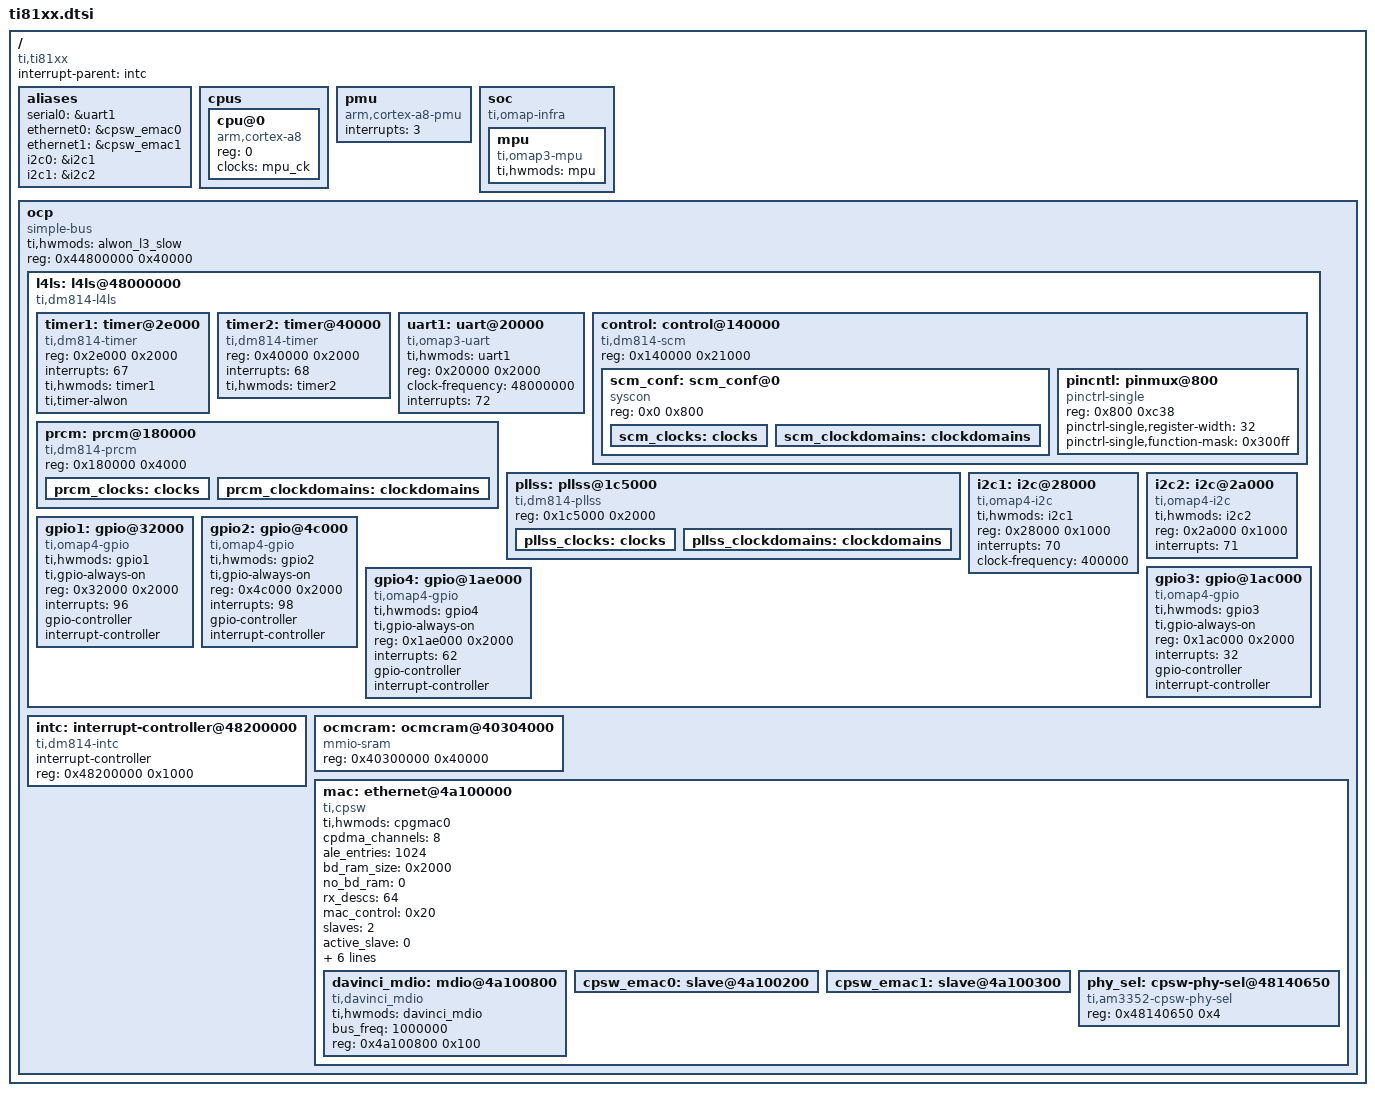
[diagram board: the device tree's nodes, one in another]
/*
 * This file is licensed under the terms of the GNU General Public License
 * version 2.  This program is licensed "as is" without any warranty of any
 * kind, whether express or implied.
 */

#include <dt-bindings/gpio/gpio.h>
#include <dt-bindings/pinctrl/omap.h>

#include "skeleton.dtsi"

/ {
	compatible = "ti,ti81xx";
	interrupt-parent = <&intc>;

	aliases {
		serial0 = &uart1;
		ethernet0 = &cpsw_emac0;
		ethernet1 = &cpsw_emac1;
		i2c0 = &i2c1;
		i2c1 = &i2c2;

	};

	cpus {
		#address-cells = <1>;
		#size-cells = <0>;
		cpu@0 {
			compatible = "arm,cortex-a8";
			device_type = "cpu";
			reg = <0>;
			clocks = <&mpu_ck>;
		};
	};

	pmu {
		compatible = "arm,cortex-a8-pmu";
		interrupts = <3>;
	};

	/*
	 * The soc node represents the soc top level view. It is used for IPs
	 * that are not memory mapped in the MPU view or for the MPU itself.
	 */
	soc {
		compatible = "ti,omap-infra";
		mpu {
			compatible = "ti,omap3-mpu";
			ti,hwmods = "mpu";
		};
	};

	ocp {
		compatible = "simple-bus";
		#address-cells = <1>;
		#size-cells = <1>;
		ranges;
		ti,hwmods = "alwon_l3_slow";
		reg = <0x44800000 0x40000>;

		/*
		 * See TRM "Table 1-317. L4LS Instance Summary", just deduct
		 * 0x1000 from the 1-317 addresses to get the device address
		 */
		l4ls: l4ls@48000000 {
			compatible = "ti,dm814-l4ls", "simple-bus";
			#address-cells = <1>;
			#size-cells = <1>;
			ranges = <0 0x48000000 0x2000000>;

			timer1: timer@2e000 {
				compatible = "ti,dm814-timer";
				reg = <0x2e000 0x2000>;
				interrupts = <67>;
				ti,hwmods = "timer1";
				ti,timer-alwon;
			};

			timer2: timer@40000 {
				compatible = "ti,dm814-timer";
				reg = <0x40000 0x2000>;
				interrupts = <68>;
				ti,hwmods = "timer2";
			};

			uart1: uart@20000 {
				compatible = "ti,omap3-uart";
				ti,hwmods = "uart1";
				reg = <0x20000 0x2000>;
				clock-frequency = <48000000>;
				interrupts = <72>;
			};

			control: control@140000 {
				compatible = "ti,dm814-scm", "simple-bus";
				reg = <0x140000 0x21000>;
				#address-cells = <1>;
				#size-cells = <1>;
				ranges = <0 0x140000 0x21000>;

				scm_conf: scm_conf@0 {
					compatible = "syscon";
					reg = <0x0 0x800>;
					#address-cells = <1>;
					#size-cells = <1>;

					scm_clocks: clocks {
						#address-cells = <1>;
						#size-cells = <0>;
					};

					scm_clockdomains: clockdomains {
					};
				};

				pincntl: pinmux@800 {
					compatible = "pinctrl-single";
					reg = <0x800 0xc38>;
					#address-cells = <1>;
					#size-cells = <0>;
					pinctrl-single,register-width = <32>;
					pinctrl-single,function-mask = <0x300ff>;
				};

			};

			prcm: prcm@180000 {
				compatible = "ti,dm814-prcm", "simple-bus";
				reg = <0x180000 0x4000>;

				prcm_clocks: clocks {
					#address-cells = <1>;
					#size-cells = <0>;
				};

				prcm_clockdomains: clockdomains {
				};
			};

			pllss: pllss@1c5000 {
				compatible = "ti,dm814-pllss", "simple-bus";
				reg = <0x1c5000 0x2000>;

				pllss_clocks: clocks {
					#address-cells = <1>;
					#size-cells = <0>;
				};

				pllss_clockdomains: clockdomains {
				};

			};
			i2c1: i2c@28000 {
				compatible = "ti,omap4-i2c";
				#address-cells = <1>;
				#size-cells = <0>;
				ti,hwmods = "i2c1";
				reg = <0x28000 0x1000>;
				interrupts = <70>;
				clock-frequency = <400000>;
			};
			i2c2: i2c@2a000 {
				compatible = "ti,omap4-i2c";
				#address-cells = <1>;
				#size-cells = <0>;
				ti,hwmods = "i2c2";
				reg = <0x2a000 0x1000>;
				interrupts = <71>;
			};
			gpio1: gpio@32000 {
				compatible = "ti,omap4-gpio";
				ti,hwmods = "gpio1";
				ti,gpio-always-on;
				reg = <0x32000 0x2000>;
				interrupts = <96>;
				gpio-controller;
				#gpio-cells = <2>;
				interrupt-controller;
				#interrupt-cells = <2>;
			};
			gpio2: gpio@4c000 {
				compatible = "ti,omap4-gpio";
				ti,hwmods = "gpio2";
				ti,gpio-always-on;
				reg = <0x4c000 0x2000>;
				interrupts = <98>;
				gpio-controller;
				#gpio-cells = <2>;
				interrupt-controller;
				#interrupt-cells = <2>;
			};
			gpio3: gpio@1ac000 {
				compatible = "ti,omap4-gpio";
				ti,hwmods = "gpio3";
				ti,gpio-always-on;
				reg = <0x1ac000 0x2000>;
				interrupts = <32>;
				gpio-controller;
				#gpio-cells = <2>;
				interrupt-controller;
				#interrupt-cells = <2>;
			};
			gpio4: gpio@1ae000 {
				compatible = "ti,omap4-gpio";
				ti,hwmods = "gpio4";
				ti,gpio-always-on;
				reg = <0x1ae000 0x2000>;
				interrupts = <62>;
				gpio-controller;
				#gpio-cells = <2>;
				interrupt-controller;
				#interrupt-cells = <2>;
			};


		};

		intc: interrupt-controller@48200000 {
			compatible = "ti,dm814-intc";
			interrupt-controller;
			#interrupt-cells = <1>;
			reg = <0x48200000 0x1000>;
		};

		ocmcram: ocmcram@40304000 {
			compatible = "mmio-sram";
			reg = <0x40300000 0x40000>; /* 256KB */
		};
		mac: ethernet@4a100000 {
			compatible = "ti,cpsw";
			ti,hwmods = "cpgmac0";
			/* clocks = <&cpsw_125mhz_gclk>, <&cpsw_cpts_rft_clk>;
			clock-names = "fck", "cpts";*/	/* ToDo */
			cpdma_channels = <8>;
			ale_entries = <1024>;
			bd_ram_size = <0x2000>;
			no_bd_ram = <0>;
			rx_descs = <64>;
			mac_control = <0x20>;
			slaves = <2>;
			active_slave = <0>;
			cpts_clock_mult = <0x80000000>;
			cpts_clock_shift = <29>;
			reg = <0x4a100000 0x800
				0x4a100900 0x100>;
			#address-cells = <1>;
			#size-cells = <1>;
			interrupt-parent = <&intc>;
			/*
			 * c0_rx_thresh_pend
			 * c0_rx_pend
			 * c0_tx_pend
			 * c0_misc_pend
			 */
			interrupts = <40 41 42 43>;
			ranges;
			syscon = <&scm_conf>;

			davinci_mdio: mdio@4a100800 {
				compatible = "ti,davinci_mdio";
				#address-cells = <1>;
				#size-cells = <0>;
				ti,hwmods = "davinci_mdio";
				bus_freq = <1000000>;
				reg = <0x4a100800 0x100>;
			};

			cpsw_emac0: slave@4a100200 {
				/* Filled in by U-Boot */
				/*mac-address = [ 00 00 00 00 00 00 ]; */
			};

			cpsw_emac1: slave@4a100300 {
				/* Filled in by U-Boot */
				/*mac-address = [ 00 00 00 00 00 00 ]; */
			};

			phy_sel: cpsw-phy-sel@48140650 {
				compatible = "ti,am3352-cpsw-phy-sel";
				reg= <0x48140650 0x4>;
				reg-names = "gmii-sel";
			};
		};
	};
};

#include "ti81xx-clocks.dtsi"
